# M55M1 register map
File version: 1.0
Registers are 32-bit, read-write, reset 0x0 unless marked. A register's access mark holds for its fields unless they carry their own. Offsets are from the block's base; [hi:lo] are bit positions; {n}, {i} and the like mark numbered series; 'fields as' and 'values as' point back to an identical list.

## LPPDMA0 — LPPDMA Register Map
Base 0x40400000
Same registers: LPPDMA0_NS 0x50400000
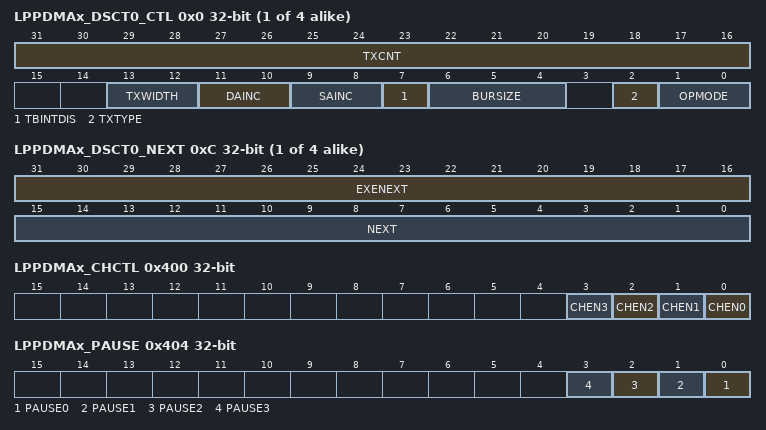
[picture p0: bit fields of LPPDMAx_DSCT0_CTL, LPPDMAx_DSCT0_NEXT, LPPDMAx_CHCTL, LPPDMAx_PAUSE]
{0x0+0x10*i} LPPDMAx_DSCT{i}_CTL reset not defined (i=0..3) — Descriptor Table Control Register of LPPDMA Channel n
  [31:16] TXCNT — Transfer Count. The TXCNT represents the required number of LPPDMA transfer, the real transfer count is (TXCNT + 1); The maximum transfer count is 65536, every transfer may be byte, half-word or word that is dependent on TXWIDTH field. Note: When LPPDMA finishes each transfer data, this field will be decreased immediately.
  [13:12] TXWIDTH — Transfer Width Selection. This field is used for transfer width. Note: The LPPDMA transfer source address (LPPDMA_DSCTn_SA) and LPPDMA transfer destination address (LPPDMA_DSCTn_DA) should be alignment under the TXWIDTH selection
    0=One byte (8 bit) is transferred for every operation; 1=One half-word (16 bit) is transferred for every operation; 2=One word (32-bit) is transferred for every operation
  [11:10] DAINC — Destination Address Increment. This field is used to set the destination address increment size. Note: The fixed address function does not support in memory to memory transfer type.
    3=No increment (fixed address)
  [9:8] SAINC — Source Address Increment. This field is used to set the source address increment size. Note: The fixed address function does not support in memory to memory transfer type.
    3=No increment (fixed address)
  [7] TBINTDIS — Table Interrupt Disable Bit. This field can be used to decide whether to enable table interrupt or not. If the TBINTDIS bit is enabled it will not generates TDIFn(LPPDMA_TDSTS[3:0]) when LPPDMA controller finishes transfer task. Note: This function only for Scatter-gather mode.
    0=Table interrupt Enabled; 1=Table interrupt Disabled
  [6:4] BURSIZE — Burst Size. This field is used for peripheral to determine the burst size or used for determine the re-arbitration size. Note: This field is only useful in burst transfer type.
    0=128 Transfers; 1=64 Transfers; 2=32 Transfers; 3=16 Transfers; 4=8 Transfers; 5=4 Transfers; 6=2 Transfers; 7=1 Transfers
  [2] TXTYPE — Transfer Type
    0=Burst transfer type; 1=Single transfer type
  [1:0] OPMODE — LPPDMA Operation Mode Selection. Note: Before filling new transfer task in the Descriptor Table, user must check the LPPDMA_INTSTS[1] to make sure the current task is complete.
    0=Idle state: Channel is stopped or this table is complete, when LPPDMA finish channel table task, OPMODE will be cleared to idle state automatically; 1=Basic mode: The descriptor table only has one task. When this task is finished, the LPPDMA_INTSTS[1] will be asserted; 2=Scatter-gather mode: When operating in this mode, user must give the next descriptor table address in LPPDMA_DSCTn_NEXT register; LPPDMA controller will ignore this task, then load the next task to execute
{0x4+0x10*i} LPPDMAx_DSCT{i}_SA reset not defined (i=0..3) — Source Address Register of LPPDMA Channel n
  [31:0] SA — LPPDMA Transfer Source Address. This field indicates a 32-bit source address of LPPDMA controller.
{0x8+0x10*i} LPPDMAx_DSCT{i}_DA reset not defined (i=0..3) — Destination Address Register of LPPDMA Channel n
  [31:0] DA — LPPDMA Transfer Destination Address. This field indicates a 32-bit destination address of LPPDMA controller.
{0xC+0x10*i} LPPDMAx_DSCT{i}_NEXT reset not defined (i=0..3) — Next Scatter-gather Descriptor Table Offset Address of LPPDMA Channel n
  [31:16] EXENEXT — LPPDMA Execution Next Descriptor Table Offset. This field indicates the offset of next descriptor table address of current execution descriptor table in system memory. Note: Write operation is useless in this field.
  [15:0] NEXT — LPPDMA Next Descriptor Table Offset. This field indicates the offset of the next descriptor table address in system memory. Read Operation: When operating in Scatter-gather mode, the last two bits NEXT[1:0] will become reserved, and indicate the first next address of system memory. Note 1: The descriptor table address must be word boundary. Note 2: Before filling transfer task in the descriptor table, user must check if the descriptor table is complete.
{0x40+4i} LPPDMAx_CURSCAT{i} ro reset not defined (i=0..3) — Current Scatter-gather Descriptor Table Address of LPPDMA Channel n
  [31:0] CURADDR — LPPDMA Current Description Address (Read Only). This field indicates a 32-bit current external description address of LPPDMA controller. Note: This field is read only and used for Scatter-gather mode only to indicate the current external description address.
0x400 LPPDMAx_CHCTL — LPPDMA Channel Control Register
  [all] fields
    0=LPPDMA channel [n] Disabled; 1=LPPDMA channel [n] Enabled
  [n] CHEN{n} (n=0..3) — LPPDMA Channel Enable Bits. Set this bit to 1 to enable LPPDMAn operation. Channel cannot be active if it is not set as enabled. Note: Setting the corresponding bit of LPPDMA_PAUSE or LPPDMA_CHRST register will also clear this bit.
0x404 LPPDMAx_PAUSE wo — LPPDMA Transfer Pause Control Register
  [all] fields
    0=No effect; 1=Pause LPPDMA channel n transfer
  [n] PAUSE{n} (n=0..3) — LPPDMA Channel n Transfer Pause Control (Write Only)
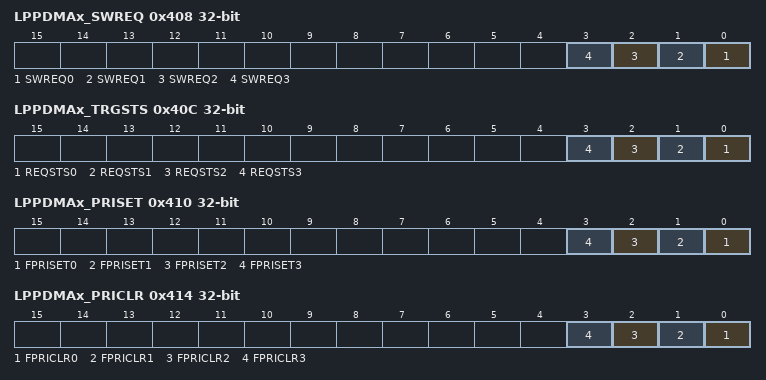
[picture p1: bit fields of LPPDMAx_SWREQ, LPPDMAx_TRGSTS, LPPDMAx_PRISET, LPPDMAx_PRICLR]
0x408 LPPDMAx_SWREQ wo — LPPDMA Software Request Register
  [all] fields
    0=No effect; 1=Generate a software request
  [n] SWREQ{n} (n=0..3) — LPPDMA Software Request (Write Only). Set this bit to 1 to generate a software request to LPPDMA [n]. Note 1: User can read LPPDMA_TRGSTS register to know which channel is on active. Active flag may be triggered by software request or peripheral request. Note 2: If user does not enable corresponding LPPDMA channel, the software request will be ignored.
0x40C LPPDMAx_TRGSTS ro — LPPDMA Channel Request Status Register
  [all] fields
    0=LPPDMA Channel n has no request; 1=LPPDMA Channel n has a request
  [n] REQSTS{n} (n=0..3) — LPPDMA Channel Request Status (Read Only). This flag indicates whether channel[n] have a request or not, no matter request from software or peripheral. When LPPDMA controller finishes channel transfer, this bit will be cleared automatically. Note: If user pauses or resets each LPPDMA transfer by setting LPPDMA_PAUSE or LPPDMA_CHRST register respectively, this bit will be cleared automatically after finishing the current transfer.
0x410 LPPDMAx_PRISET — LPPDMA Fixed Priority Setting Register
  [all] fields
    0=No effect. Corresponding LPPDMA channel is round-robin priority; 1=Set LPPDMA channel [n] to fixed priority channel. Corresponding LPPDMA channel is fixed priority
  [n] FPRISET{n} (n=0..3) — LPPDMA Fixed Priority Setting. Set this bit to 1 to enable fixed priority level. Write Operation: Note: This field is only set to fixed priority. To clear fixed priority, use LPPDMA_PRICLR register.
0x414 LPPDMAx_PRICLR wo — LPPDMA Fixed Priority Clear Register
  [all] fields
    0=No effect; 1=Clear LPPDMA channel [n] fixed priority setting
  [n] FPRICLR{n} (n=0..3) — LPPDMA Fixed Priority Clear Bits (Write Only). Set this bit to 1 to clear fixed priority level. Note: User can read LPPDMA_PRISET register to know the channel priority.
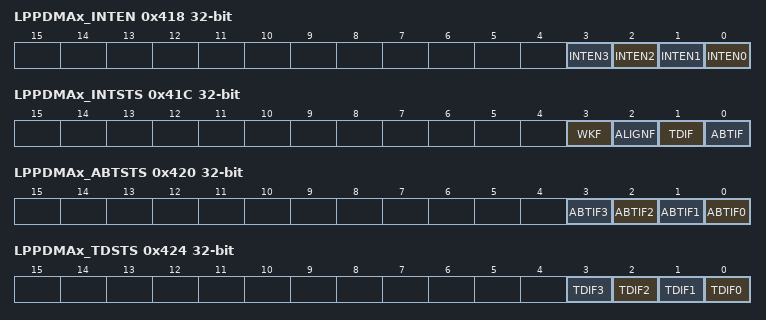
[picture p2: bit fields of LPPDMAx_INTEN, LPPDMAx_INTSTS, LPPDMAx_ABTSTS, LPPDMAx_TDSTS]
0x418 LPPDMAx_INTEN — LPPDMA Interrupt Enable Register
  [all] fields
    0=LPPDMA channel n interrupt Disabled; 1=LPPDMA channel n interrupt Enabled
  [n] INTEN{n} (n=0..3) — LPPDMA Interrupt Enable Bits. This field is used to enable LPPDMA channel[n] interrupt. Note: The interrupt flag abort, transfer done and align.
0x41C LPPDMAx_INTSTS — LPPDMA Interrupt Status Register
  [3] WKF — Wake Up Flag
    0=LPPDMA no wake up event; 1=LPPDMA wake up event happened
  [2] ALIGNF ro — Transfer Alignment Interrupt Flag (Read Only)
    0=LPPDMA channel source address and destination address both follow transfer width setting; 1=LPPDMA channel source address or destination address is not follow transfer width setting
  [1] TDIF ro — Transfer Done Interrupt Flag (Read Only). This bit indicates that LPPDMA controller has finished transmission; User can read LPPDMA_TDSTS register to indicate which channel finished transfer.
    0=Not finished yet; 1=LPPDMA channel has finished transmission
  [0] ABTIF ro — LPPDMA Read/Write Target Abort Interrupt Flag (Read Only). This bit indicates that LPPDMA has target abort error; Software can read LPPDMA_ABTSTS register to find which channel has target abort error.
    0=No AHB bus ERROR response received; 1=AHB bus ERROR response received
0x420 LPPDMAx_ABTSTS — LPPDMA Channel Read/Write Target Abort Flag Register
  [all] fields
    0=No AHB bus ERROR response received when channel n transfer; 1=AHB bus ERROR response received when channel n transfer
  [n] ABTIF{n} (n=0..3) — LPPDMA Read/Write Target Abort Interrupt Status Flag. This bit indicates which LPPDMA controller has target abort error. Note 1: If channel n target abort, REQSRCn should set0 to disable peripheral request. Note 2: User can write 1 to clear this bit.
0x424 LPPDMAx_TDSTS — LPPDMA Channel Transfer Done Flag Register
  [all] fields
    0=LPPDMA channel transfer has not finished; 1=LPPDMA channel has finished transmission
  [n] TDIF{n} (n=0..3) — Transfer Done Flag. This bit indicates whether LPPDMA controller channel transfer has been finished or not. Note: User can write 1 to clear these bits.
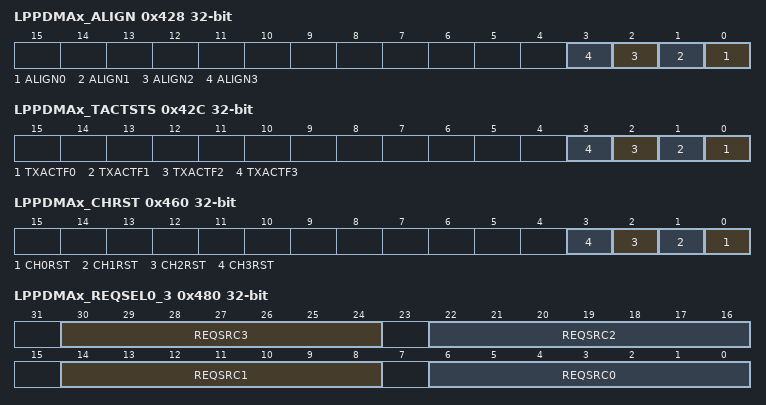
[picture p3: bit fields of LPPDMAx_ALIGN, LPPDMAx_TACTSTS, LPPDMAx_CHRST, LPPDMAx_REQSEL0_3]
0x428 LPPDMAx_ALIGN — LPPDMA Transfer Alignment Status Register
  [all] fields
    values as LPPDMAx_INTSTS.ALIGNF
  [n] ALIGN{n} (n=0..3) — Transfer Alignment Flag. This bit indicates whether source and destination address both follow transfer width setting. Note: User can write 1 to clear these bits.
0x42C LPPDMAx_TACTSTS ro — LPPDMA Transfer Active Flag Register
  [all] fields
    0=LPPDMA channel is finished; 1=LPPDMA channel is active
  [n] TXACTF{n} (n=0..3) — Transfer on Active Flag (Read Only). This bit indicates which LPPDMA channel is in active.
0x460 LPPDMAx_CHRST — LPPDMA Channel Reset Register
  [all] fields
    0=Corresponding channel n is not reset; 1=Corresponding channel n is reset
  [n] CH{n}RST (n=0..3) — Channel n Reset
0x480 LPPDMAx_REQSEL0_3 — LPPDMA Request Source Select Register 0
  [30:24] REQSRC3 — Channel 3 Request Source Selection. This filed defines which peripheral is connected to LPPDMA channel 3. User can configure the peripheral setting by REQSRC3. Note: The channel configuration is the same as REQSRC0 field. Please refer to the explanation of REQSRC0.
  [22:16] REQSRC2 — Channel 2 Request Source Selection. This filed defines which peripheral is connected to LPPDMA channel 2. User can configure the peripheral setting by REQSRC2. Note: The channel configuration is the same as REQSRC0 field. Please refer to the explanation of REQSRC0.
  [14:8] REQSRC1 — Channel 1 Request Source Selection. This filed defines which peripheral is connected to LPPDMA channel 1. User can configure the peripheral setting by REQSRC1. Note: The channel configuration is the same as REQSRC0 field. Please refer to the explanation of REQSRC0.
  [6:0] REQSRC0 — Channel 0 Request Source Selection. This filed defines which peripheral is connected to LPPDMA channel 0. User can configure the peripheral by setting REQSRC0. Note 1: A peripheral cannot be assigned to two channels at the same time. Note 2: This field is useless when transferring between memory and memory.
    0=Disable LPPDMA peripheral request; 1=Channel connects to LPUART0_TX; 2=Channel connects to LPUART0_RX; 3=Channel connects to LPSPI0_TX; 4=Channel connects to LPSPI0_RX; 5=Channel connects to LPI2C0_TX; 6=Channel connects to LPI2C0_RX; 7=Channel connects to LPTMR0; 8=Channel connects to LPTMR1; 9=Channel connects to TTMR0; 10=Channel connects to TTMR1; 11=Channel connects to LPADC0_RX; 13=Channel connects to DMIC0_RX
